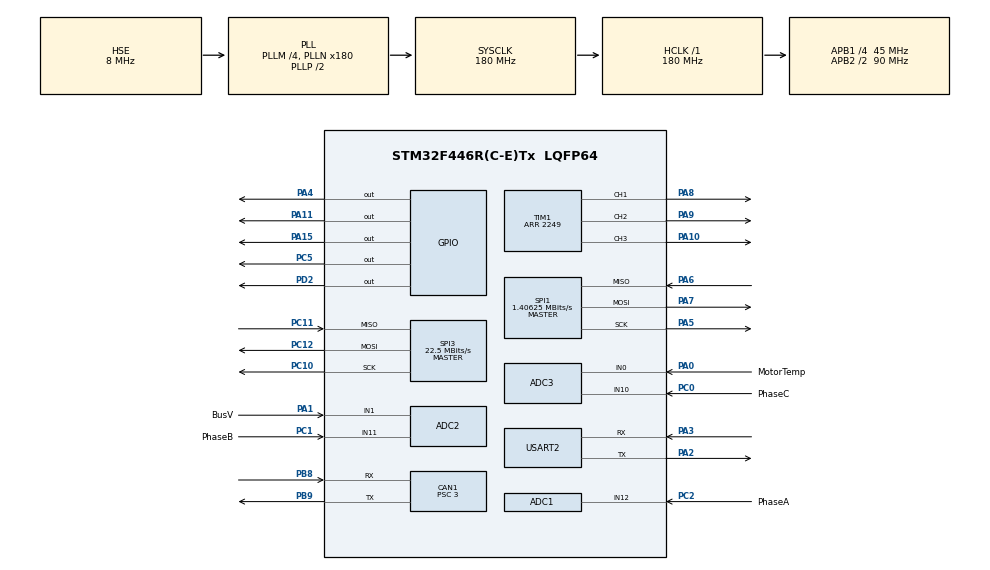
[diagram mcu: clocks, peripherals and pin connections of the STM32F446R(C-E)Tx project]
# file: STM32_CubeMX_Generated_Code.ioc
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ADC1.Channel-2\#ChannelRegularConversion=ADC_CHANNEL_12
ADC1.Channel-3\#ChannelInjectedConversion=ADC_CHANNEL_12
ADC1.ExternalTrigInjecConv=ADC_EXTERNALTRIGINJECCONV_T1_CC4
ADC1.ExternalTrigInjecConvEdge=ADC_EXTERNALTRIGINJECCONVEDGE_FALLING
ADC1.InjNumberOfConversion=1
ADC1.InjectedOffset-3\#ChannelInjectedConversion=0
ADC1.InjectedRank-3\#ChannelInjectedConversion=1
ADC1.Mode=ADC_TRIPLEMODE_INJECSIMULT
ADC1.NbrOfConversionFlag=1
ADC1.Rank-2\#ChannelRegularConversion=1
ADC1.SamplingTime-2\#ChannelRegularConversion=ADC_SAMPLETIME_3CYCLES
ADC1.SamplingTime-3\#ChannelInjectedConversion=ADC_SAMPLETIME_3CYCLES
ADC1.master=1
ADC2.Channel-0\#ChannelRegularConversion=ADC_CHANNEL_11
ADC2.Channel-1\#ChannelInjectedConversion=ADC_CHANNEL_11
ADC2.Channel-2\#ChannelInjectedConversion=ADC_CHANNEL_1
ADC2.InjNumberOfConversion=2
ADC2.InjectedOffset-1\#ChannelInjectedConversion=0
ADC2.InjectedOffset-2\#ChannelInjectedConversion=0
ADC2.InjectedRank-1\#ChannelInjectedConversion=1
ADC2.InjectedRank-2\#ChannelInjectedConversion=2
ADC2.Mode=ADC_TRIPLEMODE_INJECSIMULT
ADC2.NbrOfConversionFlag=1
ADC2.Rank-0\#ChannelRegularConversion=1
ADC2.SamplingTime-0\#ChannelRegularConversion=ADC_SAMPLETIME_3CYCLES
ADC2.SamplingTime-1\#ChannelInjectedConversion=ADC_SAMPLETIME_15CYCLES
ADC2.SamplingTime-2\#ChannelInjectedConversion=ADC_SAMPLETIME_3CYCLES
ADC3.Channel-0\#ChannelRegularConversion=ADC_CHANNEL_0
ADC3.Channel-1\#ChannelInjectedConversion=ADC_CHANNEL_10
ADC3.Channel-2\#ChannelInjectedConversion=ADC_CHANNEL_0
ADC3.InjNumberOfConversion=2
ADC3.InjectedOffset-1\#ChannelInjectedConversion=0
ADC3.InjectedOffset-2\#ChannelInjectedConversion=0
ADC3.InjectedRank-1\#ChannelInjectedConversion=1
ADC3.InjectedRank-2\#ChannelInjectedConversion=2
ADC3.NbrOfConversionFlag=1
ADC3.Rank-0\#ChannelRegularConversion=1
ADC3.SamplingTime-0\#ChannelRegularConversion=ADC_SAMPLETIME_3CYCLES
ADC3.SamplingTime-1\#ChannelInjectedConversion=ADC_SAMPLETIME_3CYCLES
ADC3.SamplingTime-2\#ChannelInjectedConversion=ADC_SAMPLETIME_3CYCLES
CAN1.BS1=CAN_BS1_12TQ
CAN1.BS2=CAN_BS2_2TQ
CAN1.CalculateBaudRate=1000000
CAN1.CalculateTimeBit=1000
CAN1.CalculateTimeQuantum=66.66666666666666
CAN1.Prescaler=3
Dma.Request0=SPI3_RX
Dma.Request1=SPI3_TX
Dma.SPI3_RX.0.Direction=DMA_PERIPH_TO_MEMORY
Dma.SPI3_RX.0.FIFOMode=DMA_FIFOMODE_DISABLE
Dma.SPI3_RX.0.Instance=DMA1_Stream0
Dma.SPI3_RX.0.MemDataAlignment=DMA_MDATAALIGN_HALFWORD
Dma.SPI3_RX.0.MemInc=DMA_MINC_ENABLE
Dma.SPI3_RX.0.Mode=DMA_NORMAL
Dma.SPI3_RX.0.PeriphDataAlignment=DMA_PDATAALIGN_HALFWORD
Dma.SPI3_RX.0.PeriphInc=DMA_PINC_DISABLE
Dma.SPI3_RX.0.Priority=DMA_PRIORITY_HIGH
Dma.SPI3_TX.1.Direction=DMA_MEMORY_TO_PERIPH
Dma.SPI3_TX.1.FIFOMode=DMA_FIFOMODE_DISABLE
Dma.SPI3_TX.1.Instance=DMA1_Stream5
Dma.SPI3_TX.1.MemDataAlignment=DMA_MDATAALIGN_HALFWORD
Dma.SPI3_TX.1.MemInc=DMA_MINC_ENABLE
Dma.SPI3_TX.1.Mode=DMA_NORMAL
Dma.SPI3_TX.1.PeriphDataAlignment=DMA_PDATAALIGN_HALFWORD
Dma.SPI3_TX.1.PeriphInc=DMA_PINC_DISABLE
Dma.SPI3_TX.1.Priority=DMA_PRIORITY_LOW
Mcu.Family=STM32F4
Mcu.Name=STM32F446R(C-E)Tx
Mcu.Package=LQFP64
NVIC.ADC_IRQn=true\:0\:0\:false\:false\:true\:true\:true\:true
NVIC.CAN1_RX0_IRQn=true\:10\:0\:true\:false\:true\:true\:true\:true
NVIC.DMA1_Stream0_IRQn=true\:0\:0\:false\:false\:true\:false\:true\:true
NVIC.DMA1_Stream5_IRQn=true\:0\:0\:false\:false\:true\:false\:true\:true
NVIC.PriorityGroup=NVIC_PRIORITYGROUP_4
NVIC.TIM1_UP_TIM10_IRQn=true\:0\:0\:false\:false\:true\:true\:true\:true
NVIC.USART2_IRQn=true\:0\:0\:false\:false\:true\:true\:true\:true
PA0-WKUP.GPIO_Label=MotorTemp
PA0-WKUP.Signal=ADCx_IN0
PA1.GPIO_Label=BusV
PA1.Signal=ADCx_IN1
PA10.GPIO_Speed=GPIO_SPEED_FREQ_VERY_HIGH
PA10.Signal=S_TIM1_CH3
PA11.GPIO_Speed=GPIO_SPEED_FREQ_VERY_HIGH
PA11.Signal=GPIO_Output
PA13.Mode=Serial_Wire
PA13.Signal=SYS_JTMS-SWDIO
PA14.Mode=Serial_Wire
PA14.Signal=SYS_JTCK-SWCLK
PA15.GPIO_Speed=GPIO_SPEED_FREQ_VERY_HIGH
PA15.Signal=GPIO_Output
PA2.Mode=Asynchronous
PA2.Signal=USART2_TX
PA3.Mode=Asynchronous
PA3.Signal=USART2_RX
PA4.GPIO_Speed=GPIO_SPEED_FREQ_VERY_HIGH
PA4.Signal=GPIO_Output
PA5.Mode=Full_Duplex_Master
PA5.Signal=SPI1_SCK
PA6.Mode=Full_Duplex_Master
PA6.Signal=SPI1_MISO
PA7.Mode=Full_Duplex_Master
PA7.Signal=SPI1_MOSI
PA8.GPIO_Speed=GPIO_SPEED_FREQ_VERY_HIGH
PA8.Signal=S_TIM1_CH1
PA9.GPIO_Speed=GPIO_SPEED_FREQ_VERY_HIGH
PA9.Signal=S_TIM1_CH2
PB8.Mode=CAN_Activate
PB8.Signal=CAN1_RX
PB9.Mode=CAN_Activate
PB9.Signal=CAN1_TX
PC0.GPIO_Label=PhaseC
PC0.Signal=ADCx_IN10
PC1.GPIO_Label=PhaseB
PC1.Signal=ADCx_IN11
PC10.Mode=Full_Duplex_Master
PC10.Signal=SPI3_SCK
PC11.Mode=Full_Duplex_Master
PC11.Signal=SPI3_MISO
PC12.Mode=Full_Duplex_Master
PC12.Signal=SPI3_MOSI
PC2.GPIO_Label=PhaseA
PC2.Signal=ADCx_IN12
PC5.GPIO_Speed=GPIO_SPEED_FREQ_VERY_HIGH
PC5.Signal=GPIO_Output
PD2.Signal=GPIO_Output
PH0-OSC_IN.Mode=HSE-External-Oscillator
PH0-OSC_IN.Signal=RCC_OSC_IN
PH1-OSC_OUT.Mode=HSE-External-Oscillator
PH1-OSC_OUT.Signal=RCC_OSC_OUT
ProjectManager.HeapSize=0x200
ProjectManager.StackSize=0x400
ProjectManager.TargetToolchain=CMake
RCC.AHBFreq_Value=180000000
RCC.APB1CLKDivider=RCC_HCLK_DIV4
RCC.APB1Freq_Value=45000000
RCC.APB1TimFreq_Value=90000000
RCC.APB2CLKDivider=RCC_HCLK_DIV2
RCC.APB2Freq_Value=90000000
RCC.APB2TimFreq_Value=180000000
RCC.CortexFreq_Value=180000000
RCC.HCLKFreq_Value=180000000
RCC.HSE_VALUE=8000000
RCC.PLLM=4
RCC.PLLN=180
RCC.PLLSourceVirtual=RCC_PLLSOURCE_HSE
RCC.SYSCLKFreq_VALUE=180000000
RCC.SYSCLKSource=RCC_SYSCLKSOURCE_PLLCLK
RCC.USBFreq_Value=180000000
RCC.VCOOutputFreq_Value=360000000
SH.ADCx_IN0.0=ADC3_IN0,IN0
SH.ADCx_IN1.0=ADC2_IN1,IN1
SH.ADCx_IN10.0=ADC3_IN10,IN10
SH.ADCx_IN11.0=ADC2_IN11,IN11
SH.ADCx_IN12.0=ADC1_IN12,IN12
SH.S_TIM1_CH1.0=TIM1_CH1,PWM Generation1 CH1
SH.S_TIM1_CH2.0=TIM1_CH2,PWM Generation2 CH2
SH.S_TIM1_CH3.0=TIM1_CH3,PWM Generation3 CH3
SPI1.BaudRatePrescaler=SPI_BAUDRATEPRESCALER_64
SPI1.CLKPhase=SPI_PHASE_2EDGE
SPI1.CalculateBaudRate=1.40625 MBits/s
SPI1.DataSize=SPI_DATASIZE_16BIT
SPI1.Direction=SPI_DIRECTION_2LINES
SPI1.Mode=SPI_MODE_MASTER
SPI1.VirtualType=VM_MASTER
SPI3.CalculateBaudRate=22.5 MBits/s
SPI3.DataSize=SPI_DATASIZE_16BIT
SPI3.Direction=SPI_DIRECTION_2LINES
SPI3.Mode=SPI_MODE_MASTER
SPI3.VirtualType=VM_MASTER
TIM1.AutoReloadPreload=TIM_AUTORELOAD_PRELOAD_ENABLE
TIM1.Channel-PWM\ Generation1\ CH1=TIM_CHANNEL_1
TIM1.Channel-PWM\ Generation2\ CH2=TIM_CHANNEL_2
TIM1.Channel-PWM\ Generation3\ CH3=TIM_CHANNEL_3
TIM1.Channel-PWM\ Generation4\ No\ Output=TIM_CHANNEL_4
TIM1.CounterMode=TIM_COUNTERMODE_CENTERALIGNED1
TIM1.OCFastMode_PWM-PWM\ Generation1\ CH1=TIM_OCFAST_ENABLE
TIM1.OCFastMode_PWM-PWM\ Generation2\ CH2=TIM_OCFAST_ENABLE
TIM1.OCFastMode_PWM-PWM\ Generation3\ CH3=TIM_OCFAST_ENABLE
TIM1.OCFastMode_PWM-PWM\ Generation4\ No\ Output=TIM_OCFAST_ENABLE
TIM1.Period=2249
TIM1.TIM_MasterOutputTrigger=TIM_TRGO_RESET
USART2.VirtualMode=VM_ASYNC
VP_TIM1_VS_ClockSourceINT.Mode=Internal
VP_TIM1_VS_no_output4.Mode=PWM Generation4 No Output
board=custom

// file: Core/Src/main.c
/* USER CODE BEGIN Header */
/**
  ******************************************************************************
  * @file           : main.c
  * @brief          : Main program body
  ******************************************************************************
  * @attention
  *
  * Copyright (c) 2026 STMicroelectronics.
  * All rights reserved.
  *
  * This software is licensed under terms that can be found in the LICENSE file
  * in the root directory of this software component.
  * If no LICENSE file comes with this software, it is provided AS-IS.
  *
  ******************************************************************************
  */
/* USER CODE END Header */
#include "main.h"
#include "adc.h"
#include "can.h"
#include "dma.h"
#include "spi.h"
#include "tim.h"
#include "usart.h"
#include "gpio.h"

/* USER CODE BEGIN Includes */
#include "MainProMax.hpp"
/* USER CODE END Includes */

void SystemClock_Config(void);

int main(void)
{

  /* MCU Configuration--------------------------------------------------------*/

  /* Reset of all peripherals, Initializes the Flash interface and the Systick. */
  HAL_Init();

  /* Configure the system clock */
  SystemClock_Config();

  /* Initialize all configured peripherals */
  MX_GPIO_Init();
  MX_DMA_Init();
  MX_ADC1_Init();
  MX_ADC2_Init();
  MX_ADC3_Init();
  MX_CAN1_Init();
  MX_SPI1_Init();
  MX_SPI3_Init();
  MX_TIM1_Init();
  MX_USART2_UART_Init();

  /* Infinite loop */
  /* USER CODE BEGIN WHILE */
  mainProMax();
  /* USER CODE END WHILE */
}

void SystemClock_Config(void)
{
  RCC_OscInitTypeDef RCC_OscInitStruct = {0};
  RCC_ClkInitTypeDef RCC_ClkInitStruct = {0};

  /** Configure the main internal regulator output voltage
  */
  __HAL_RCC_PWR_CLK_ENABLE();
  __HAL_PWR_VOLTAGESCALING_CONFIG(PWR_REGULATOR_VOLTAGE_SCALE1);

  /** Initializes the RCC Oscillators according to the specified parameters
  * in the RCC_OscInitTypeDef structure.
  */
  RCC_OscInitStruct.OscillatorType = RCC_OSCILLATORTYPE_HSE;
  RCC_OscInitStruct.HSEState = RCC_HSE_ON;
  RCC_OscInitStruct.PLL.PLLState = RCC_PLL_ON;
  RCC_OscInitStruct.PLL.PLLSource = RCC_PLLSOURCE_HSE;
  RCC_OscInitStruct.PLL.PLLM = 4;
  RCC_OscInitStruct.PLL.PLLN = 180;
  RCC_OscInitStruct.PLL.PLLP = RCC_PLLP_DIV2;
  RCC_OscInitStruct.PLL.PLLQ = 2;
  RCC_OscInitStruct.PLL.PLLR = 2;
  if (HAL_RCC_OscConfig(&RCC_OscInitStruct) != HAL_OK)
  {
    Error_Handler();
  }

  /** Activate the Over-Drive mode
  */
  if (HAL_PWREx_EnableOverDrive() != HAL_OK)
  {
    Error_Handler();
  }

  /** Initializes the CPU, AHB and APB buses clocks
  */
  RCC_ClkInitStruct.ClockType = RCC_CLOCKTYPE_HCLK|RCC_CLOCKTYPE_SYSCLK
                              |RCC_CLOCKTYPE_PCLK1|RCC_CLOCKTYPE_PCLK2;
  RCC_ClkInitStruct.SYSCLKSource = RCC_SYSCLKSOURCE_PLLCLK;
  RCC_ClkInitStruct.AHBCLKDivider = RCC_SYSCLK_DIV1;
  RCC_ClkInitStruct.APB1CLKDivider = RCC_HCLK_DIV4;
  RCC_ClkInitStruct.APB2CLKDivider = RCC_HCLK_DIV2;

  if (HAL_RCC_ClockConfig(&RCC_ClkInitStruct, FLASH_LATENCY_5) != HAL_OK)
  {
    Error_Handler();
  }
}

void Error_Handler(void)
{
  __disable_irq();
  while (1)
  {
  }
}
